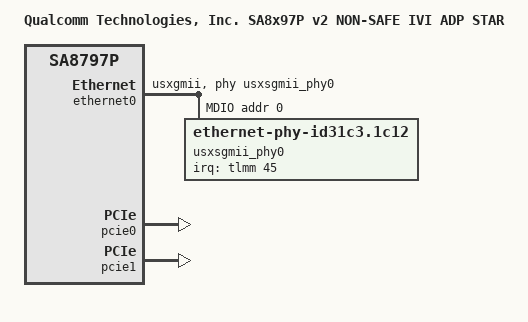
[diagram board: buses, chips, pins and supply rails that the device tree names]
// SPDX-License-Identifier: BSD-3-Clause
/*
 * Copyright (c) Qualcomm Technologies, Inc. and/or its subsidiaries.
 */

/dts-v1/;

#include "sa8x97p.dtsi"
#include "sa8x97p-v2.dtsi"
#include "sa8797p.dtsi"
#include "sa8x97p-non-safe.dtsi"

/ {
	model = "Qualcomm Technologies, Inc. SA8x97P v2 NON-SAFE IVI ADP STAR";
	compatible = "qcom,sa8x97p-adp-star", "qcom,sa8x97p-adp", "qcom,sa8797p";
	qcom,msm-id = <689 0x20000>, <690 0x20000>;
	qcom,board-id = <0x010025 0>;

	aliases {
		serial0 = &uart15;
	};
};

&xpcs0 {
	/delete-property/ interrupts;
	/delete-property/ interrupt-names;
};

&ethernet0 {
	phy-mode = "usxgmii";
	phy-handle = <&usxsgmii_phy0>;

	/delete-property/ interrupts;
	/delete-property/ interrupt-names;

	interrupts = <GIC_SPI 821 IRQ_TYPE_LEVEL_HIGH>,
		     <GIC_SPI 689 IRQ_TYPE_LEVEL_HIGH>,
		     <GIC_SPI 524 IRQ_TYPE_LEVEL_HIGH>,
		     <GIC_SPI 525 IRQ_TYPE_LEVEL_HIGH>,
		     <GIC_SPI 522 IRQ_TYPE_LEVEL_HIGH>,
		     <GIC_SPI 526 IRQ_TYPE_LEVEL_HIGH>,
		     <GIC_SPI 519 IRQ_TYPE_LEVEL_HIGH>,
		     <GIC_SPI 520 IRQ_TYPE_LEVEL_HIGH>,
		     <GIC_SPI 462 IRQ_TYPE_LEVEL_HIGH>,
		     <GIC_SPI 521 IRQ_TYPE_LEVEL_HIGH>,
		     <GIC_SPI 158 IRQ_TYPE_LEVEL_HIGH>;
	interrupt-names = "macirq", "dma_tx_rx0", "dma_tx_rx1", "dma_tx_rx2",
			 "dma_tx_rx3", "dma_tx_rx4", "dma_tx_rx5", "dma_tx_rx6",
			 "dma_tx_rx7", "dma_tx_rx8", "dma_tx_rx9";

	mdio {
		compatible = "snps,dwmac-mdio";
		#address-cells = <1>;
		#size-cells = <0>;

		usxsgmii_phy0: phy@0 {
			compatible = "ethernet-phy-id31c3.1c12";
			reg = <0x0>;
			device_type = "ethernet-phy";
			interrupts-extended = <&tlmm 45 IRQ_TYPE_EDGE_FALLING>;
			resets = <&scmi7_rst 0>;
			reset-names = "phy";
			reset-assert-us = <100000>;
			reset-deassert-us = <100000>;
		};
	};
};

&xpcs1 {
	status = "disabled";
};

&ethernet1 {
	status = "disabled";

	phy-mode = "usxgmii";
	phy-handle = <&usxsgmii_phy1>;

	mdio {
		compatible = "snps,dwmac-mdio";
		#address-cells = <1>;
		#size-cells = <0>;

		usxsgmii_phy1: phy@8 {
			compatible = "ethernet-phy-id31c3.1c12";
			reg = <0x8>;
			device_type = "ethernet-phy";
			interrupts-extended = <&tlmm 46 IRQ_TYPE_EDGE_FALLING>;
			resets = <&scmi8_rst 0>;
			reset-names = "phy";
			reset-assert-us = <100000>;
			reset-deassert-us = <100000>;
		};
	};
};

&pcie0 {
	power-domains = <&scmi5_pd 0>;
	power-domain-names = "power";
	status = "okay";
};

&pcie1 {
	power-domains = <&scmi6_pd 0>;
	power-domain-names = "power";
	status = "okay";
};
